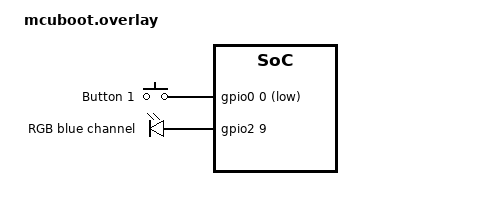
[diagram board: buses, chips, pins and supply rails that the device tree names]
#include "../partitions.dtsi"
#include "../usb_uart.dtsi"
/ {
	chosen {
		zephyr,code-partition = &boot_partition;
		zephyr,uart-mcumgr = &uart00;
	};

	buttons {
		compatible = "gpio-keys";

		button0: button_0 {
			gpios = <&gpio0 0 (GPIO_PULL_UP | GPIO_ACTIVE_LOW)>;
			label = "Button 1";
		};
	};

	leds {
		compatible = "gpio-leds";
		blue_led: led_1 {
			gpios = <&gpio2 9 0>;
			label = "RGB blue channel";
		};
	};

	aliases {
		mcuboot-led0 = &blue_led;
		mcuboot-button0 = &button0;
	};
};


